# Cortex_M7 register map
Vendor: Arm Ltd.; Series: ARMv7E-M; File version: 1.0.0
CPU: CM7 r0p0, little endian, MPU, FPU, double-precision FPU, DSP, 8 interrupt priority bits
Registers are 32-bit, read-write, reset 0x0 unless marked. A register's access mark holds for its fields unless they carry their own. Offsets are from the block's base; [hi:lo] are bit positions; {n}, {i} and the like mark numbered series.

## DWT — Data Watchpoint and Trace unit: cycle counter and profiling counters, PC sampling, exception trace, and address/data comparators that raise watchpoints (halt or DebugMonitor), trigger the ETM/CTI or emit data trace. Needs DEMCR.TRCENA = 1.
Base 0xE0001000
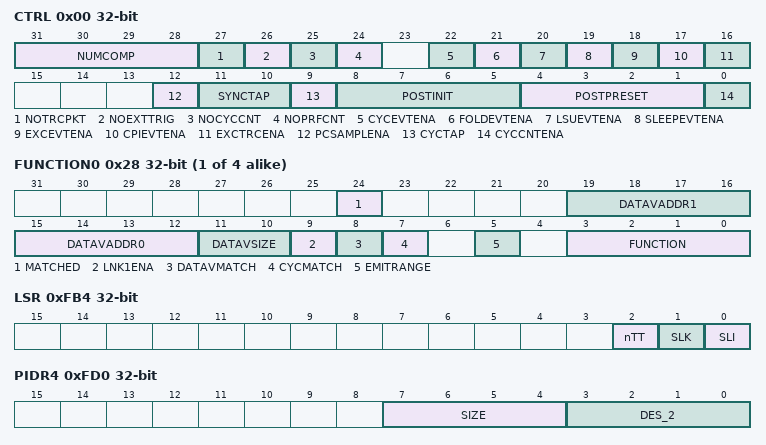
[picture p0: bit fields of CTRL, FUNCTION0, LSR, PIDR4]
0x00 CTRL — DWT Control Register: cycle counter, PC sampling, exception trace and profiling event enables; read-only capability bits (NUMCOMP, NOCYCCNT...) in the top byte.
  [31:28] NUMCOMP ro — Number of comparators implemented (0-15; 4 on most Cortex-M3/M4/M7/M33 devices). Read-only.
  [27] NOTRCPKT ro — 1 = trace sampling and exception tracing (PC samples, data trace, exception trace) are not implemented. Read-only.
  [26] NOEXTTRIG ro — 1 = the CMPMATCH trigger outputs are not implemented. Read-only.
  [25] NOCYCCNT ro — 1 = CYCCNT is not implemented. Read-only.
  [24] NOPRFCNT ro — 1 = the profiling counters (CPICNT, EXCCNT, SLEEPCNT, LSUCNT, FOLDCNT) are not implemented. Read-only.
  [22] CYCEVTENA — Enable the POSTCNT underflow (cycle count) event packet.
  [21] FOLDEVTENA — Enable the folded-instruction counter overflow event packet.
  [20] LSUEVTENA — Enable the LSU counter overflow event packet.
  [19] SLEEPEVTENA — Enable the sleep counter overflow event packet.
  [18] EXCEVTENA — Enable the exception overhead counter overflow event packet.
  [17] CPIEVTENA — Enable the CPI counter overflow event packet.
  [16] EXCTRCENA — Exception trace enable: emit packets on every exception entry, exit and return.
  [12] PCSAMPLENA — Periodic PC sample packets enable: a PC sample is emitted through the ITM every POSTCNT underflow (statistical profiling over SWO).
  [11:10] SYNCTAP — Synchronization packet interval (with TCR.SYNCENA): 0 = disabled, 1 = every 2^24 cycles (CYCCNT bit 24), 2 = 2^26, 3 = 2^28.
  [9] CYCTAP — CYCCNT tap that decrements POSTCNT: 0 = bit 6 (every 64 cycles), 1 = bit 10 (every 1024 cycles).
  [8:5] POSTINIT — Initial value of POSTCNT.
  [4:1] POSTPRESET — Reload value for the POSTCNT down-counter that divides the CYCTAP rate for PC sampling and CYCEVT events (0 = every tap).
  [0] CYCCNTENA — Cycle counter enable: 1 = CYCCNT counts (DEMCR.TRCENA must be 1). Reset value 0.
0x04 CYCCNT — Cycle Count Register: counts processor clock cycles while CTRL.CYCCNTENA = 1 (and DEMCR.TRCENA), wrapping at 2^32. Read for cycle-accurate timing; write to reset.
  [31:0] CYCCNT — Cycle count. Writable; write 0 to restart a measurement.
0x08 CPICNT — CPI Count Register: extra cycles (beyond the first) of every instruction, 8-bit, generating a CPI event on overflow when CTRL.CPIEVTENA is set.
  [7:0] CPICNT — Current CPI count (extra cycles per instruction), wraps at 256 with an event.
0x0C EXCCNT — Exception Overhead Count Register: cycles spent in exception entry and exit, 8-bit, event on overflow.
  [7:0] EXCCNT — Current exception overhead count, wraps at 256 with an event.
0x10 SLEEPCNT — Sleep Count Register: cycles spent sleeping, 8-bit, event on overflow.
  [7:0] SLEEPCNT — Current sleep cycle count, wraps at 256 with an event.
0x14 LSUCNT — LSU Count Register: extra cycles spent by load/store instructions, 8-bit, event on overflow.
  [7:0] LSUCNT — Current load/store extra-cycle count, wraps at 256 with an event.
0x18 FOLDCNT — Folded-instruction Count Register: instructions that took zero cycles (folded), 8-bit, event on overflow.
  [7:0] FOLDCNT — Current folded-instruction count, wraps at 256 with an event.
0x1C PCSR ro — Program Counter Sample Register: the address of a recently executed instruction - read repeatedly by a debugger for non-intrusive statistical profiling. 0xFFFFFFFF when halted.
  [31:0] EIASAMPLE — Sampled instruction address (0xFFFFFFFF when the processor is halted or PCSR is not implemented).
{0x20+0x10*i} COMP{i} (i=0..3) — Comparator Register {i}
  [31:0] COMP — Reference value for the comparator: an address, a data value (DATAVMATCH / MATCH = data value) or a cycle count.
{0x24+0x10*i} MASK{i} (i=0..3) — Mask Register {i}
  [4:0] MASK — Log2 of the number of low address bits ignored by the comparator (0 = exact match, 4 = 16-byte range ...). The maximum supported value is found by writing all ones and reading back.
{0x28+0x10*i} FUNCTION{i} (i=0..3) — Function Register {i}
  [24] MATCHED — The comparator matched since this register was last read. Cleared on read.
  [19:16] DATAVADDR1 — Number of the second linked address comparator (only if LNK1ENA = 1).
  [15:12] DATAVADDR0 — Number of the comparator that supplies the address match for data-value matching (DATAVMATCH = 1).
  [11:10] DATAVSIZE — Size of the data value to match: 0 = byte, 1 = halfword, 2 = word.
  [9] LNK1ENA ro — Read-only: 1 = a second linked address comparator (DATAVADDR1) is supported for data value matching.
  [8] DATAVMATCH — 1 = compare the data value of the access (COMPn) rather than the address; DATAVADDR0/1 select the comparators that match the address.
  [7] CYCMATCH — Comparator 0 only: 1 = compare CYCCNT against COMP0 instead of an address.
  [5] EMITRANGE — 1 = emit data-trace address offset packets instead of the full address (data trace functions 1-3 and 12-15).
  [3:0] FUNCTION — ARMv7-M comparator function: 0 disabled; 1 emit PC sample on match, 2 emit data value, 3 emit PC and data value; 4 watchpoint on instruction fetch (PC), 5 watchpoint on read, 6 watchpoint on write, 7 watchpoint on read or write; 8-15 ETM trigger / data trace variants. With CYCMATCH: 1 = event, 4 = watchpoint on cycle count match.
0xFB0 LAR wo — Lock Access Register
  [31:0] KEY — Write 0xC5ACCE55 to unlock the DWT registers for software writes; any other value locks them.
0xFB4 LSR ro — Lock Status Register
  [2] nTT — 0 = 32-bit lock access.
  [1] SLK — Locked: 1 = software writes are ignored.
  [0] SLI — Software lock implemented.
0xFD0 PIDR4 ro — Peripheral Identification Register 4: JEP106 continuation code and component size.
  [7:4] SIZE — Log2 of the number of 4 KB blocks the component occupies (0 = one block).
  [3:0] DES_2 — JEP106 continuation code of the designer (Arm: 0x4).
{0xFC0+4i} PIDR{i} ro (i=5..7) — Peripheral Identification Register {i} (reserved, reads as zero).
0xFE0 PIDR0 ro — Peripheral Identification Register 0: part number bits [7:0].
  [7:0] PART_0 — Part number bits [7:0].
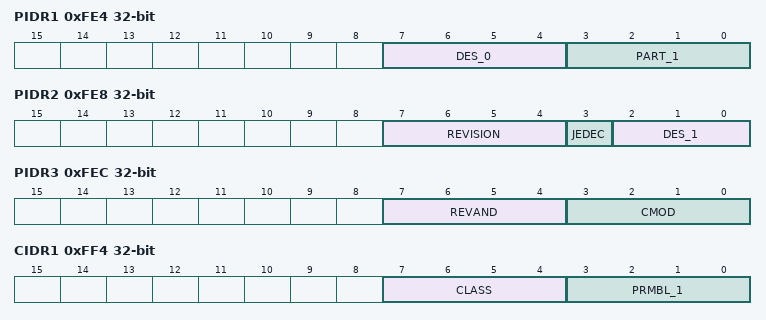
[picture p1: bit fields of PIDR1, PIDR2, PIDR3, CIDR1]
0xFE4 PIDR1 ro — Peripheral Identification Register 1: part number bits [11:8] and designer bits [3:0].
  [7:4] DES_0 — JEP106 identity code bits [3:0] of the designer.
  [3:0] PART_1 — Part number bits [11:8].
0xFE8 PIDR2 ro — Peripheral Identification Register 2: designer bits [6:4], JEDEC flag and revision.
  [7:4] REVISION — Component major revision.
  [3] JEDEC — Always 1: the designer ID is a JEDEC JEP106 code.
  [2:0] DES_1 — JEP106 identity code bits [6:4] of the designer.
0xFEC PIDR3 ro — Peripheral Identification Register 3: customer modified and minor revision.
  [7:4] REVAND — Minor revision (metal fix) number.
  [3:0] CMOD — Customer Modified: 0 if the component has not been modified by the integrator.
0xFF0 CIDR0 ro — Component Identification Register 0: preamble byte 0 (0x0D).
  [7:0] PRMBL_0 — Preamble, reads as 0x0D.
0xFF4 CIDR1 ro — Component Identification Register 1: component class and preamble.
  [7:4] CLASS — Component class: 0x1 ROM table, 0x9 CoreSight component, 0xE generic IP, 0xF CoreLink/PrimeCell.
  [3:0] PRMBL_1 — Preamble, reads as 0x0.
0xFF8 CIDR2 ro — Component Identification Register 2: preamble byte 2 (0x05).
  [7:0] PRMBL_2 — Preamble, reads as 0x05.
0xFFC CIDR3 ro — Component Identification Register 3: preamble byte 3 (0xB1).
  [7:0] PRMBL_3 — Preamble, reads as 0xB1.
